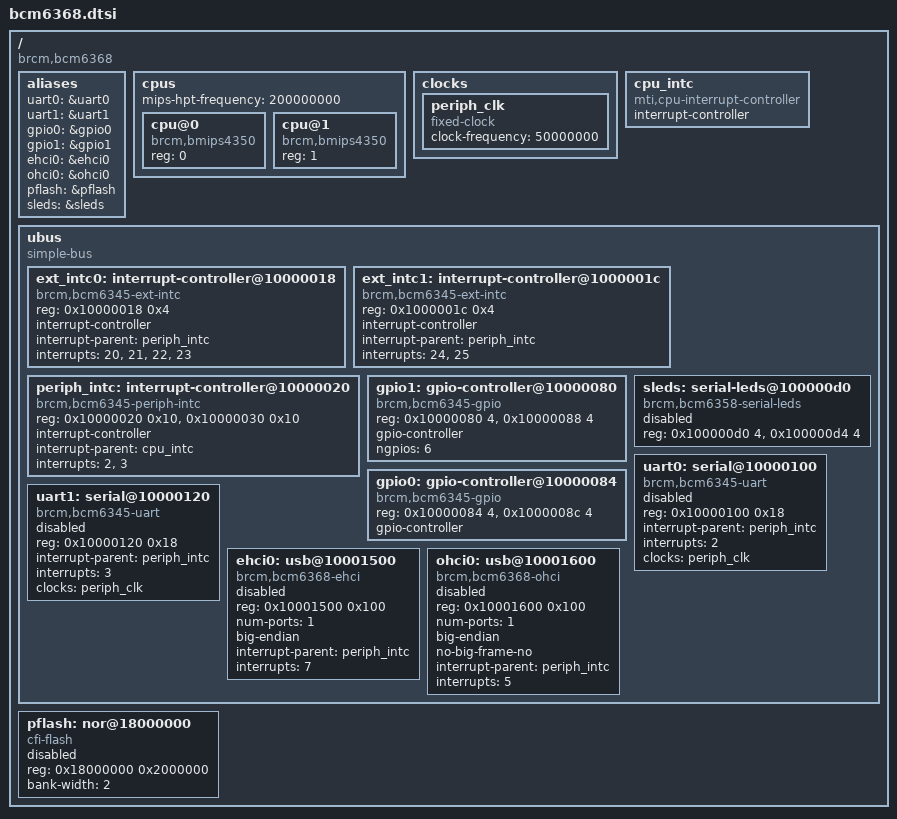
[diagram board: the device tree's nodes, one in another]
/ {
	#address-cells = <1>;
	#size-cells = <1>;
	compatible = "brcm,bcm6368";

	aliases {
		uart0 = &uart0;
		uart1 = &uart1;
		gpio0 = &gpio0;
		gpio1 = &gpio1;
		ehci0 = &ehci0;
		ohci0 = &ohci0;
		pflash = &pflash;
		sleds = &sleds;
	};

	cpus {
		#address-cells = <1>;
		#size-cells = <0>;

		mips-hpt-frequency = <200000000>;

		cpu@0 {
			compatible = "brcm,bmips4350";
			device_type = "cpu";
			reg = <0>;
		};

		cpu@1 {
			compatible = "brcm,bmips4350";
			device_type = "cpu";
			reg = <1>;
		};
	};

	clocks {
		periph_clk: periph_clk {
			compatible = "fixed-clock";
			#clock-cells = <0>;
			clock-frequency = <50000000>;
		};
	};

	cpu_intc: cpu_intc {
		#address-cells = <0>;
		compatible = "mti,cpu-interrupt-controller";

		interrupt-controller;
		#interrupt-cells = <1>;
	};

	ubus {
		#address-cells = <1>;
		#size-cells = <1>;

		compatible = "simple-bus";
		ranges;

		ext_intc0: interrupt-controller@10000018 {
			compatible = "brcm,bcm6345-ext-intc";
			reg = <0x10000018 0x4>;

			interrupt-controller;
			#interrupt-cells = <2>;

			interrupt-parent = <&periph_intc>;
			interrupts = <20>, <21>, <22>, <23>;
		};

		ext_intc1: interrupt-controller@1000001c {
			compatible = "brcm,bcm6345-ext-intc";
			reg = <0x1000001c 0x4>;

			interrupt-controller;
			#interrupt-cells = <2>;

			interrupt-parent = <&periph_intc>;
			interrupts = <24>, <25>;
		};

		periph_intc: interrupt-controller@10000020 {
			compatible = "brcm,bcm6345-periph-intc";
			reg = <0x10000020 0x10>,
			      <0x10000030 0x10>;

			interrupt-controller;
			#interrupt-cells = <1>;

			interrupt-parent = <&cpu_intc>;
			interrupts = <2>, <3>;
		};

		gpio1: gpio-controller@10000080 {
			compatible = "brcm,bcm6345-gpio";
			reg = <0x10000080 4>, <0x10000088 4>;

			gpio-controller;
			#gpio-cells = <2>;

			ngpios = <6>;
		};

		gpio0: gpio-controller@10000084 {
			compatible = "brcm,bcm6345-gpio";
			reg = <0x10000084 4>, <0x1000008c 4>;

			gpio-controller;
			#gpio-cells = <2>;
		};

		sleds: serial-leds@100000d0 {
			compatible = "brcm,bcm6358-serial-leds";
			reg = <0x100000d0 4>, <0x100000d4 4>;
			reg-names = "dat", "ctl";

			status = "disabled";
		};

		uart0: serial@10000100 {
			compatible = "brcm,bcm6345-uart";
			reg = <0x10000100 0x18>;
			interrupt-parent = <&periph_intc>;
			interrupts = <2>;
			clocks = <&periph_clk>;
			status = "disabled";
		};

		uart1: serial@10000120 {
			compatible = "brcm,bcm6345-uart";
			reg = <0x10000120 0x18>;
			interrupt-parent = <&periph_intc>;
			interrupts = <3>;
			clocks = <&periph_clk>;
			status = "disabled";
		};

		ehci0: usb@10001500 {
			compatible = "brcm,bcm6368-ehci", "generic-ehci";
			reg = <0x10001500 0x100>;
			num-ports = <1>;
			big-endian;
			interrupt-parent = <&periph_intc>;
			interrupts = <7>;
			status = "disabled";
		};

		ohci0: usb@10001600 {
			compatible = "brcm,bcm6368-ohci", "generic-ohci";
			reg = <0x10001600 0x100>;
			num-ports = <1>;
			big-endian;
			no-big-frame-no;
			interrupt-parent = <&periph_intc>;
			interrupts = <5>;
			status = "disabled";
		};
	};

	pflash: nor@18000000 {
		compatible = "cfi-flash";
		reg = <0x18000000 0x2000000>;
		bank-width = <2>;
		#address-cells = <1>;
		#size-cells = <1>;
		status = "disabled";
	};
};
